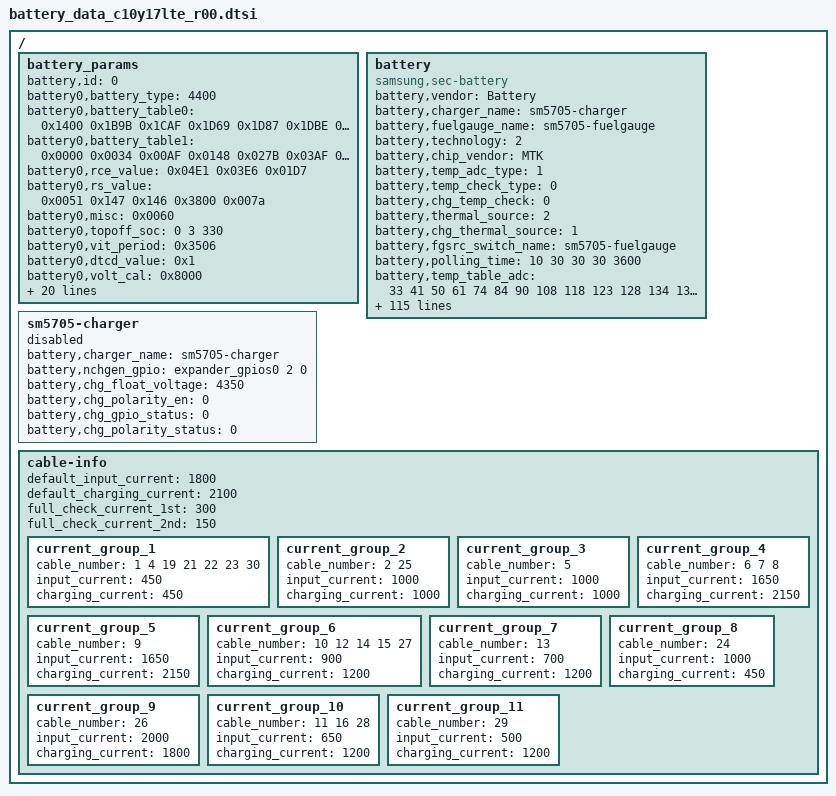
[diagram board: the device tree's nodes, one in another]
/*
 * C10 2017 Battery parameters device tree file
 *
 * Copyright (C) 2017 Samsung Electronics, Inc.
 *
 * This program is free software; you can redistribute it and/or
 * modify it under the terms of the GNU General Public License
 * as published by the Free Software Foundation; either version 2
 * of the License, or (at your option) any later version.
 *
 * This program is distributed in the hope that it will be useful,
 * but WITHOUT ANY WARRANTY; without even the implied warranty of
 * MERCHANTABILITY or FITNESS FOR A PARTICULAR PURPOSE.  See the
 * GNU General Public License for more details.
 *
 * You should have received a copy of the GNU General Public License
 * along with this program. If not, see <http://www.gnu.org/licenses/>.
 *
 */

/ {
	battery_params {
		battery,id = <0>; /* -1 means auto, detected by F/G */
		battery0,battery_type = <4400>; /* 4200 4350 4400 */
		battery0,battery_table0 = <0x1400 0x1B9B 0x1CAF 0x1D69 0x1D87 0x1DBE 0x1DF2 0x1E3F 0x1E8D 0x1ED3 0x1F18 0x1F8F 0x203B 0x2159 0x2252 0x2400>;
		battery0,battery_table1 = <0x0000 0x0034 0x00AF 0x0148 0x027B 0x03AF 0x04E2 0x0748 0x0A48 0x0C15 0x0D48 0x0E7B 0x10E2 0x141F 0x1686 0x1691>;
		battery0,rce_value = <0x04E1 0x03E6 0x01D7>;
		battery0,rs_value = <0x0051 0x147 0x146 0x3800 0x007a>; /*rs p_mix_factor n_mix_factor max min*/
		battery0,misc = <0x0060>;
		battery0,topoff_soc = <0 3 330>; /*enable soc current*/
		battery0,vit_period = <0x3506>;
		battery0,dtcd_value = <0x1>;
		battery0,volt_cal = <0x8000>;
		battery0,curr_offset = <1 0x0000>; /*en_auto offset*/
		battery0,p_curr_cal = <0x0080>;
		battery0,n_curr_cal = <0x0078>;
		battery0,mix_value = <0x0403 0x0004>; /*mix_rate init_blank*/
		battery0,temp_std = <25>;
		battery0,temp_cal = <1 6 1 11 (-1) 1 6 1 9 1>; /* en_h, p_de, p_fa, n_de, n_fa, en_l, p_de, p_fa, n_de, n_fa, */
		battery0,ext_temp_cal = <0 2 1 2 1 1 2 3 2 3>; /* en_h, p_de, p_fa, n_de, n_fa, en_l, p_de, p_fa, n_de, n_fa, */
		battery0,temp_volcal = <1 45 1>; /* en, temp, cal */
		battery0,temp_offset = <1 11 1 1 8 (-1)>; /* en_high level offset en_low level offset */
		battery0,cycle_cfg = <7 1 3>; /*high_limit low_limit cntl*/
		battery0,curr_lcal = <0 0x8888 0x8888 0x8888>;
		battery0,tem_poff = <3400 50 3300 50>;
		battery0,v_offset_cancel = <1 0 100 2>; /* en_p, en_n, level, mohm */
		battery0,v_alarm = <3200>;
		battery0,full_offset = <20 4>; /*margin extra_offset*/
		battery0,v_max_table = <0x2274 0x223D 0x2214 0x21EB 0x219C>; /* For long life of battery */
		battery0,q_max_table = <0x1915 0x18A3 0x1830 0x17BE 0x16A0>; /* For long life of battery */
		battery0,data_ver = <0x03>;
	};

	battery {
		status = "okay";
		compatible = "samsung,sec-battery";

		pinctrl-names = "default";

		battery,vendor = "Battery";
		battery,charger_name = "sm5705-charger";
		battery,fuelgauge_name = "sm5705-fuelgauge";
		battery,technology = <2>; /* POWER_SUPPLY_TECHNOLOGY_LION */

		battery,chip_vendor = "MTK";
		battery,temp_adc_type = <1>; /* SEC_BATTERY_ADC_TYPE_AP */

		battery,temp_check_type = <0>; /* SEC_BATTERY_TEMP_CHECK_TEMP */
		battery,chg_temp_check = <0>;

		battery,thermal_source = <2>; /* SEC_BATTERY_THERMAL_SOURCE_ADC */
		battery,chg_thermal_source = <1>; /* SEC_CHARGER_THERMAL_SOURCE_ADC */

		battery,fgsrc_switch_name = "sm5705-fuelgauge";

		battery,polling_time = <10 30 30 30 3600>;

		battery,temp_table_adc = <
					33 41 50 61 74 84 90 108 118 123
					128 134 139 146 153 161 165 173 181 190
					195 200 210 218 227 235 244 255 264 275
					281 297 309 320 334 347 361 374 392 419
					436 451 485 505 523 540 562 576 602 620
					640 664 684 705 729 750 776 800 823 841
					873 898 950 1000 1052 1075 1099 1129 1252 1371
					1453 1499 
					>;

		battery,temp_table_data = <
					850 800 750 700 650 610 600 550 540 530
					520 510 500 490 480 470 460 450 440 430
					420 410 400 390 380 370 360 350 340 330
					320 310 300 290 280 270 260 250 240 230
					210 200 190 170 160 150 140 130 120 110
					100 90 80 70 60 50 40 30 20 10
					0 (-10) (-30) (-50) (-80) (-90) (-100) (-110) (-160) (-210)
					(-250) (-300)
					>;

		battery,chg_temp_table_adc = <
					139 158 163 169 189 195 202 428 443 455
					499 513 531 566 582 652 678 694 992 1006
					1030 1086 1117 1120 1209 1226 1243 1292 1313 1337
					1386 1401 1415
					>;

		battery,chg_temp_table_data = <
					850 810 800 790 760 750 740 510 500 490
					460 450 440 420 410 370 360 350 210 200
					190 160 150 140 110 100 90 60 50 40
					10 0 (-10)
					>;

		battery,adc_check_count = <5>;

		battery,cable_check_type = <4>; /* SEC_BATTERY_CABLE_CHECK_PSY */
		battery,cable_source_type = <1>; /* SEC_BATTERY_CABLE_SOURCE_EXTERNAL */
		battery,polling_type = <1>; /* SEC_BATTERY_MONITOR_ALARM */
		battery,monitor_initial_count = <0>;

		battery,battery_check_type = <0>; /* SEC_BATTERY_CHECK_NONE */
		battery,check_count = <0>;
		battery,check_adc_max = <1440>;
		battery,check_adc_min = <0>;

		battery,ovp_uvlo_check_type = <3>; /* SEC_BATTERY_OVP_UVLO_CHGPOLLING */

		battery,temp_check_count = <1>;
		battery,temp_highlimit_threshold_event = <800>;
		battery,temp_highlimit_recovery_event = <750>;
		battery,temp_high_threshold_event = <500>;
		battery,temp_high_recovery_event = <450>;
		battery,temp_low_threshold_event = <(0)>;
		battery,temp_low_recovery_event = <50>;
		battery,temp_highlimit_threshold_normal = <800>;
		battery,temp_highlimit_recovery_normal = <750>;
		battery,temp_high_threshold_normal = <500>;
		battery,temp_high_recovery_normal = <450>;
		battery,temp_low_threshold_normal = <(0)>;
		battery,temp_low_recovery_normal = <50>;
		battery,temp_highlimit_threshold_lpm = <800>;
		battery,temp_highlimit_recovery_lpm = <750>;
		battery,temp_high_threshold_lpm = <500>;
		battery,temp_high_recovery_lpm = <450>;
		battery,temp_low_threshold_lpm = <(0)>;
		battery,temp_low_recovery_lpm = <50>;
		battery,wpc_high_threshold_normal = <450>;
		battery,wpc_high_recovery_normal = <400>;
		battery,wpc_low_threshold_normal = <(0)>;
		battery,wpc_low_recovery_normal = <50>;
		battery,full_check_type = <2>; /* SEC_BATTERY_FULLCHARGED_FG_CURRENT */
		battery,full_check_type_2nd = <2>; /* SEC_BATTERY_FULLCHARGED_FG_CURRENT */
		battery,full_check_count = <1>;
		battery,chg_gpio_full_check = <0>;
		battery,chg_polarity_full_check = <1>;

		battery,chg_high_temp = <460>;
		battery,chg_high_temp_recovery = <440>;
		battery,chg_input_limit_current = <1000>;
		battery,chg_charging_limit_current = <1250>; 

		battery,wpc_high_temp = <410>;
		battery,wpc_high_temp_recovery = <400>;
		battery,wpc_charging_limit_current = <450>;
		battery,wpc_lcd_on_high_temp = <430>;
		battery,wpc_lcd_on_high_temp_rec = <300>;

		battery,sleep_mode_limit_current = <500>;
		battery,wc_full_input_limit_current = <100>;
		battery,wc_cv_current = <820>;
		battery,wc_cv_pack_current = <630>;

		battery,mix_high_temp = <420>;
		battery,mix_high_chg_temp = <500>;
		battery,mix_high_temp_recovery = <390>;

		/* SEC_BATTERY_FULL_CONDITION_SOC |
		   SEC_BATTERY_FULL_CONDITION_NOTIMEFULL |
		   SEC_BATTERY_FULL_CONDITION_VCELL */
		battery,full_condition_type = <13>;
		battery,full_condition_soc = <93>;
		battery,full_condition_vcell = <4250>;

		battery,recharge_check_count = <1>;
		battery,recharge_condition_type = <4>; /* SEC_BATTERY_RECHARGE_CONDITION_VCELL */
		battery,recharge_condition_soc = <98>;
		battery,recharge_condition_vcell = <4300>;

		battery,charging_total_time = <14400>;
		battery,hv_charging_total_time = <10800>;
		battery,normal_charging_total_time = <18000>;
		battery,usb_charging_total_time = <36000>;
		battery,recharging_total_time = <5400>;
		battery,charging_reset_time = <0>;

		battery,chg_float_voltage = <4350>;

		battery,swelling_high_temp_block = <410>;
		battery,swelling_high_temp_recov = <360>;
		battery,swelling_low_temp_block_1st = <150>;
		battery,swelling_low_temp_recov_1st = <200>;
		battery,swelling_low_temp_block_2nd = <50>;
		battery,swelling_low_temp_recov_2nd = <100>;

		battery,swelling_low_temp_current = <700>;	/* 0.3C */
		battery,swelling_low_temp_topoff = <165>;	/* 0.05C */
		battery,swelling_high_temp_current = <1050>;	/* 0.45C */
		battery,swelling_high_temp_topoff = <165>;	/* 0.05C */
		battery,swelling_wc_high_temp_current = <700>;	/* 0.3C */
		battery,swelling_wc_low_temp_current = <700>;	/* 0.3C */

		battery,swelling_drop_float_voltage = <4150>;
		battery,swelling_high_rechg_voltage = <4000>;
		battery,swelling_low_rechg_voltage = <4000>;

		battery,siop_event_check_type = <1>;
		battery,siop_call_cv_current = <330>;
		battery,siop_call_cc_current = <330>;

		battery,siop_input_limit_current = <1200>;
		battery,siop_charging_limit_current = <1000>;
		battery,siop_hv_input_limit_current = <500>;
		battery,siop_hv_charging_limit_current = <1000>;

		battery,siop_wireless_input_limit_current = <600>;
		battery,siop_wireless_charging_limit_current = <700>;
		battery,siop_hv_wireless_input_limit_current = <600>;
		battery,siop_hv_wireless_charging_limit_current = <700>;

		battery,ttf_hv_charge_current = <2150>;
		battery,ttf_hv_wireless_charge_current = <1150>;

		battery,pd_charging_charge_power = <15000>;
		battery,max_charging_current = <2150>;
		battery,battery_full_capacity = <3000>;

		/* cycle, chg_float_voltage, recharge_condition_vcell, full_condition_vcell, full_condition_soc */
		battery,age_data = <0 4350 4300 4250 93
				200 4330 4280 4230 89
				250 4310 4260 4210 85
				300 4290 4240 4190 80
				1000 4240 4190 4140 75>;

		battery,max_input_voltage = <12000>; /* mV */
		battery,max_input_current = <3000>;  /* mA */

		battery,standard_curr = <2150>;
		battery,expired_time = <10800>;
		battery,recharging_expired_time = <5400>;
	};

	sm5705-charger {
		status = "disable";
		/* Charger */
		battery,charger_name = "sm5705-charger";
		battery,nchgen_gpio = <&expander_gpios0 2 0>;
		battery,chg_float_voltage = <4350>;

		battery,chg_polarity_en = <0>;
		battery,chg_gpio_status = <0>;
		battery,chg_polarity_status = <0>;
	};

/* sec_battery_cable
 *   0	UNKNOWN,
 *   1	NONE,
 *   2	PREPARE_TA,
 *   3	TA,
 *   4	USB,
 *   5	USB_CDP,
 *   6	9V_TA,
 *   7	9V_ERR,
 *   8	9V_UNKNOWN,
 *   9	12V_TA,
 *  10	WIRELESS,
 *  11	HV_WIRELESS,
 *  12	PMA_WIRELESS,
 *  13	WIRELESS_PACK,
 *  14	WIRELESS_PACK_TA,
 *  15	WIRELESS_STAND,
 *  16	WIRELESS_HV_STAND,
 *  17	QC20,
 *  18	QC30,
 *  19	PDIC,
 *  20	UARTOFF,
 *  21	OTG,
 *  22	LAN_HUB,
 *  23	POWER_SHARING,
 *  24	HMT_CONNECTED,
 *  25	HMT_CHARGE,
 *  26	HV_TA_CHG_LIMIT,
 *  27	WIRELESS_VEHICLE,
 *  28	WIRELESS_HV_VEHICLE,
 *  29	PREPARE_WIRELESS_HV,
 *  30	TIMEOUT,
 *  31	CABLE_MAX,
*/
	cable-info{
		default_input_current = <1800>;
		default_charging_current = <2100>;
		full_check_current_1st = <300>;
		full_check_current_2nd = <150>;

		current_group_1 {
			cable_number = <1 4 19 21 22 23 30>;
			input_current = <450>;
			charging_current = <450>;
		};
		current_group_2 {
			cable_number = <2 25>;
			input_current = <1000>;
			charging_current = <1000>;
		};
		current_group_3 {
			cable_number = <5>;
			input_current = <1000>;
			charging_current = <1000>;
		};
		current_group_4 {
			cable_number = <6 7 8>;
			input_current = <1650>;
			charging_current = <2150>;
		};
		current_group_5 {
			cable_number = <9>;
			input_current = <1650>;
			charging_current = <2150>;
		};
		current_group_6 {
			cable_number = <10 12 14 15 27>;
			input_current = <900>;
			charging_current = <1200>;
		};
		current_group_7 {
			cable_number = <13>;
			input_current = <700>;
			charging_current = <1200>;
		};
		current_group_8 {
			cable_number = <24>;
			input_current = <1000>;
			charging_current = <450>;
		};
		current_group_9 {
			cable_number = <26>;
			input_current = <2000>;
			charging_current = <1800>;
		};
		current_group_10 {
			cable_number = <11 16 28>;
			input_current = <650>;
			charging_current = <1200>;
		};
		current_group_11 {
			cable_number = <29>;
			input_current = <500>;
			charging_current = <1200>;
		};
	};
};
